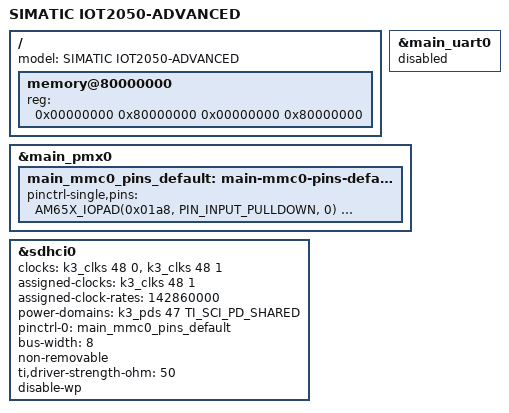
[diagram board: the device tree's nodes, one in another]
// SPDX-License-Identifier: GPL-2.0
/*
 * (C) Copyright 2019 Siemens AG
 */

/dts-v1/;

#include "../ti/k3-am654.dtsi"
#include "iot2050-common.dtsi"

/ {
	model = "SIMATIC IOT2050-ADVANCED";

	memory@80000000 {
		device_type = "memory";
		/* 2G RAM */
		reg = <0x00000000 0x80000000 0x00000000 0x80000000>;
	};
};

&main_uart0 {
	status = "disabled";
};

&main_pmx0 {
	main_mmc0_pins_default: main-mmc0-pins-default {
		pinctrl-single,pins = <
			AM65X_IOPAD(0x01a8, PIN_INPUT_PULLDOWN, 0)  /* (B25) MMC0_CLK */
			AM65X_IOPAD(0x01ac, PIN_INPUT_PULLUP,   0)  /* (B27) MMC0_CMD */
			AM65X_IOPAD(0x01a4, PIN_INPUT_PULLUP,   0)  /* (A26) MMC0_DAT0 */
			AM65X_IOPAD(0x01a0, PIN_INPUT_PULLUP,   0)  /* (E25) MMC0_DAT1 */
			AM65X_IOPAD(0x019c, PIN_INPUT_PULLUP,   0)  /* (C26) MMC0_DAT2 */
			AM65X_IOPAD(0x0198, PIN_INPUT_PULLUP,   0)  /* (A25) MMC0_DAT3 */
			AM65X_IOPAD(0x0194, PIN_INPUT_PULLUP,   0)  /* (E24) MMC0_DAT4 */
			AM65X_IOPAD(0x0190, PIN_INPUT_PULLUP,   0)  /* (A24) MMC0_DAT5 */
			AM65X_IOPAD(0x018c, PIN_INPUT_PULLUP,   0)  /* (B26) MMC0_DAT6 */
			AM65X_IOPAD(0x0188, PIN_INPUT_PULLUP,   0)  /* (D25) MMC0_DAT7 */
			AM65X_IOPAD(0x01B8, PIN_OUTPUT_PULLUP,  7)  /* (B23) MMC0_SDWP */
			AM65X_IOPAD(0x01b4, PIN_INPUT_PULLUP,   0)  /* (A23) MMC0_SDCD */
			AM65X_IOPAD(0x01b0, PIN_INPUT,          0)  /* (C25) MMC0_DS */
		>;
	};
};

&sdhci0 {
	/*
	 * Swap clock TISCI clock IDs between sdhci0 and sdhci1 to work
	 * around an issue in System Firmware 2019.12a (and earlier) known
	 * as SYSFW-3179.
	 */
	clocks = <&k3_clks 48 0>, <&k3_clks 48 1>;
	assigned-clocks = <&k3_clks 48 1>;
	assigned-clock-rates = <142860000>;

	power-domains = <&k3_pds 47 TI_SCI_PD_SHARED>;

	pinctrl-names = "default";
	pinctrl-0 = <&main_mmc0_pins_default>;
	bus-width = <8>;
	non-removable;
	ti,driver-strength-ohm = <50>;
	disable-wp;
};
